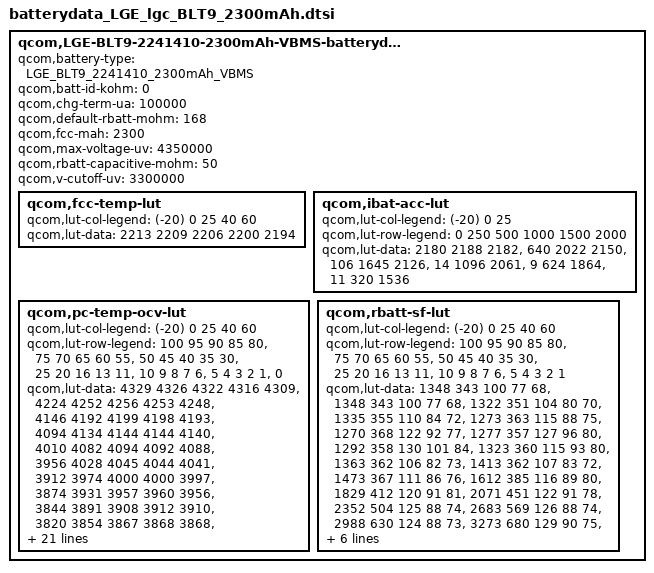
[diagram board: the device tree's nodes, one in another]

qcom,LGE-BLT9-2241410-2300mAh-VBMS-batterydata {
	qcom,battery-type = "LGE_BLT9_2241410_2300mAh_VBMS";
	qcom,batt-id-kohm = <0>;
	qcom,chg-term-ua = <100000>;
	qcom,default-rbatt-mohm = <168>;
	qcom,fcc-mah = <2300>;
	qcom,max-voltage-uv = <4350000>;
	qcom,rbatt-capacitive-mohm = <50>;
	qcom,v-cutoff-uv = <3300000>;

	qcom,fcc-temp-lut {
		qcom,lut-col-legend = <(-20) 0 25 40 60>;
		qcom,lut-data = <2213 2209 2206 2200 2194>;
	};

	qcom,ibat-acc-lut {
		qcom,lut-col-legend = <(-20) 0 25>;
		qcom,lut-row-legend = <0 250 500 1000 1500 2000>;
		qcom,lut-data = <2180 2188 2182>,
				<640 2022 2150>,
				<106 1645 2126>,
				<14 1096 2061>,
				<9 624 1864>,
				<11 320 1536>;
	};

	qcom,pc-temp-ocv-lut {
		qcom,lut-col-legend = <(-20) 0 25 40 60>;
		qcom,lut-row-legend = <100 95 90 85 80>,
					<75 70 65 60 55>,
					<50 45 40 35 30>,
					<25 20 16 13 11>,
					<10 9 8 7 6>,
					<5 4 3 2 1>,
					<0>;
		qcom,lut-data = <4329 4326 4322 4316 4309>,
				<4224 4252 4256 4253 4248>,
				<4146 4192 4199 4198 4193>,
				<4094 4134 4144 4144 4140>,
				<4010 4082 4094 4092 4088>,
				<3956 4028 4045 4044 4041>,
				<3912 3974 4000 4000 3997>,
				<3874 3931 3957 3960 3956>,
				<3844 3891 3908 3912 3910>,
				<3820 3854 3867 3868 3868>,
				<3798 3822 3838 3839 3838>,
				<3776 3794 3815 3816 3815>,
				<3754 3774 3796 3796 3796>,
				<3732 3760 3780 3779 3778>,
				<3710 3747 3766 3763 3756>,
				<3687 3734 3750 3744 3731>,
				<3662 3718 3724 3718 3704>,
				<3639 3702 3695 3688 3674>,
				<3616 3687 3681 3676 3664>,
				<3598 3676 3676 3670 3660>,
				<3588 3670 3674 3668 3658>,
				<3576 3663 3672 3666 3656>,
				<3563 3654 3667 3661 3646>,
				<3550 3642 3660 3656 3636>,
				<3534 3622 3638 3630 3608>,
				<3510 3594 3597 3588 3567>,
				<3478 3555 3547 3536 3516>,
				<3431 3494 3483 3473 3452>,
				<3359 3408 3399 3392 3366>,
				<3240 3270 3283 3265 3232>,
				<3000 3000 3000 3000 3000>;
	};

	qcom,rbatt-sf-lut {
		qcom,lut-col-legend = <(-20) 0 25 40 60>;
		qcom,lut-row-legend = <100 95 90 85 80>,
					<75 70 65 60 55>,
					<50 45 40 35 30>,
					<25 20 16 13 11>,
					<10 9 8 7 6>,
					<5 4 3 2 1>;
		qcom,lut-data = <1348 343 100 77 68>,
				<1348 343 100 77 68>,
				<1322 351 104 80 70>,
				<1335 355 110 84 72>,
				<1273 363 115 88 75>,
				<1270 368 122 92 77>,
				<1277 357 127 96 80>,
				<1292 358 130 101 84>,
				<1323 360 115 93 80>,
				<1363 362 106 82 73>,
				<1413 362 107 83 72>,
				<1473 367 111 86 76>,
				<1612 385 116 89 80>,
				<1829 412 120 91 81>,
				<2071 451 122 91 78>,
				<2352 504 125 88 74>,
				<2683 569 126 88 74>,
				<2988 630 124 88 73>,
				<3273 680 129 90 75>,
				<3552 712 139 95 78>,
				<3699 728 146 99 79>,
				<3865 739 154 102 81>,
				<4050 744 161 104 80>,
				<4086 731 165 107 79>,
				<4221 700 151 96 77>,
				<4704 720 146 97 79>,
				<5343 752 152 100 82>,
				<6211 782 162 110 88>,
				<7730 850 180 115 92>,
				<11341 1129 202 129 108>;
	};
};
